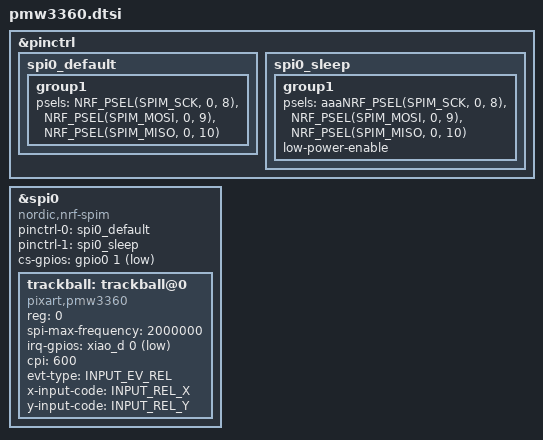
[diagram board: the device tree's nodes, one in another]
&pinctrl {
    spi0_default: spi0_default {
        group1 {
            psels = <NRF_PSEL(SPIM_SCK, 0, 8)>,
                <NRF_PSEL(SPIM_MOSI, 0, 9)>,
                <NRF_PSEL(SPIM_MISO, 0, 10)>;
        };
    };

    spi0_sleep: spi0_sleep {
        group1 {
            psels = <aaaNRF_PSEL(SPIM_SCK, 0, 8)>,
                <NRF_PSEL(SPIM_MOSI, 0, 9)>,
                <NRF_PSEL(SPIM_MISO, 0, 10)>;
            low-power-enable;
        };
    };
};

#include <zephyr/dt-bindings/input/input-event-codes.h>
&spi0 {
    status = "okay";
    compatible = "nordic,nrf-spim";
    pinctrl-0 = <&spi0_default>;
    pinctrl-1 = <&spi0_sleep>;
    pinctrl-names = "default", "sleep";
    cs-gpios = <&gpio0 1 GPIO_ACTIVE_LOW>;

    trackball: trackball@0 {
        compatible = "pixart,pmw3360";
        reg = <0>;
        spi-max-frequency = <2000000>;
        irq-gpios = <&xiao_d 0 (GPIO_ACTIVE_LOW | GPIO_PULL_UP)>;
        status = "okay";
		cpi = <600>;
        evt-type = <INPUT_EV_REL>;
        x-input-code = <INPUT_REL_X>;
        y-input-code = <INPUT_REL_Y>;
    };
};
